# LM3S2139 register map
File version: 7944
Registers are 32-bit, read-write, no defined reset value unless marked. A register's access mark holds for its fields unless they carry their own. Offsets are from the block's base; [hi:lo] are bit positions; {n}, {i} and the like mark numbered series.

## COMP — Register map for COMP peripheral
Base 0x4003C000; register names take the prefix COMP
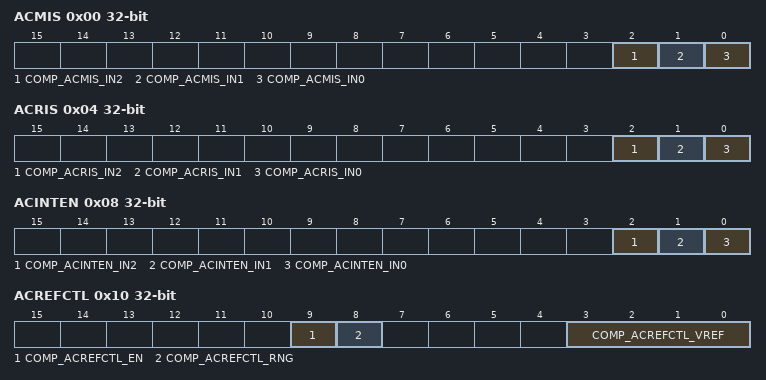
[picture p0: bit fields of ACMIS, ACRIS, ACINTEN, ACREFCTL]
0x00 ACMIS — Analog Comparator Masked Interrupt Status
  [2] COMP_ACMIS_IN2 — Comparator 2 Masked Interrupt Status
  [1] COMP_ACMIS_IN1 — Comparator 1 Masked Interrupt Status
  [0] COMP_ACMIS_IN0 — Comparator 0 Masked Interrupt Status
0x04 ACRIS — Analog Comparator Raw Interrupt Status
  [2] COMP_ACRIS_IN2 — Comparator 2 Interrupt Status
  [1] COMP_ACRIS_IN1 — Comparator 1 Interrupt Status
  [0] COMP_ACRIS_IN0 — Comparator 0 Interrupt Status
0x08 ACINTEN — Analog Comparator Interrupt Enable
  [2] COMP_ACINTEN_IN2 — Comparator 2 Interrupt Enable
  [1] COMP_ACINTEN_IN1 — Comparator 1 Interrupt Enable
  [0] COMP_ACINTEN_IN0 — Comparator 0 Interrupt Enable
0x10 ACREFCTL — Analog Comparator Reference Voltage Control
  [9] COMP_ACREFCTL_EN — Resistor Ladder Enable
  [8] COMP_ACREFCTL_RNG — Resistor Ladder Range
  [3:0] COMP_ACREFCTL_VREF — Resistor Ladder Voltage Ref
{0x20+0x20*i} ACSTAT{i} (i=0..2) — Analog Comparator Status {i}
  [1] COMP_ACSTAT{i}_OVAL — Comparator Output Value
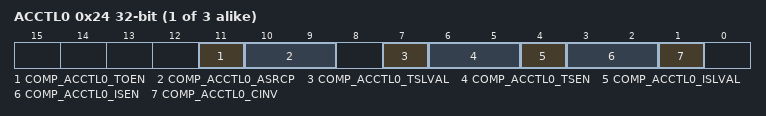
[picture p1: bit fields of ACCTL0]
{0x24+0x20*i} ACCTL{i} (i=0..2) — Analog Comparator Control {i}
  [11] COMP_ACCTL{i}_TOEN — Trigger Output Enable
  [10:9] COMP_ACCTL{i}_ASRCP — Analog Source Positive
    0=COMP_ACCTL{i}_ASRCP_PIN (Pin value of Cn+); 1=COMP_ACCTL{i}_ASRCP_PIN0 (Pin value of C0+); 2=COMP_ACCTL{i}_ASRCP_REF (Internal voltage reference (VIREF))
  [7] COMP_ACCTL{i}_TSLVAL — Trigger Sense Level Value
  [6:5] COMP_ACCTL{i}_TSEN — Trigger Sense
    0=COMP_ACCTL{i}_TSEN_LEVEL (Level sense, see TSLVAL); 1=COMP_ACCTL{i}_TSEN_FALL (Falling edge); 2=COMP_ACCTL{i}_TSEN_RISE (Rising edge); 3=COMP_ACCTL{i}_TSEN_BOTH (Either edge)
  [4] COMP_ACCTL{i}_ISLVAL — Interrupt Sense Level Value
  [3:2] COMP_ACCTL{i}_ISEN — Interrupt Sense
    0=COMP_ACCTL{i}_ISEN_LEVEL (Level sense, see ISLVAL); 1=COMP_ACCTL{i}_ISEN_FALL (Falling edge); 2=COMP_ACCTL{i}_ISEN_RISE (Rising edge); 3=COMP_ACCTL{i}_ISEN_BOTH (Either edge)
  [1] COMP_ACCTL{i}_CINV — Comparator Output Invert

## FLASH_CTRL — Register map for FLASH_CTRL peripheral
Base 0x400FD000; register names take the prefix FLASH_CTRL
0x00 FMA — Flash Memory Address
  [15:0] FLASH_FMA_OFFSET — Address Offset
0x04 FMD — Flash Memory Data
  [31:0] FLASH_FMD_DATA — Data Value
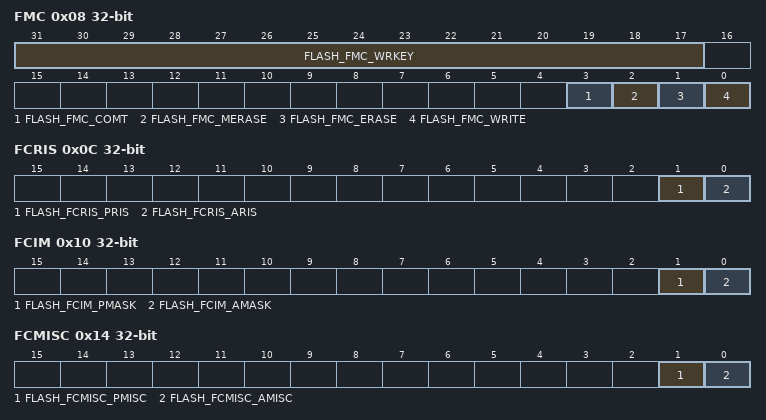
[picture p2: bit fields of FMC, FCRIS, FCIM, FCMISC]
0x08 FMC — Flash Memory Control
  [31:17] FLASH_FMC_WRKEY — FLASH write key
  [3] FLASH_FMC_COMT — Commit Register Value
  [2] FLASH_FMC_MERASE — Mass Erase Flash Memory
  [1] FLASH_FMC_ERASE — Erase a Page of Flash Memory
  [0] FLASH_FMC_WRITE — Write a Word into Flash Memory
0x0C FCRIS — Flash Controller Raw Interrupt Status
  [1] FLASH_FCRIS_PRIS — Programming Raw Interrupt Status
  [0] FLASH_FCRIS_ARIS — Access Raw Interrupt Status
0x10 FCIM — Flash Controller Interrupt Mask
  [1] FLASH_FCIM_PMASK — Programming Interrupt Mask
  [0] FLASH_FCIM_AMASK — Access Interrupt Mask
0x14 FCMISC — Flash Controller Masked Interrupt Status and Clear
  [1] FLASH_FCMISC_PMISC — Programming Masked Interrupt Status and Clear
  [0] FLASH_FCMISC_AMISC — Access Masked Interrupt Status and Clear
0x1140 USECRL — USec Reload
  [7:0] FLASH_USECRL — Microsecond Reload Value
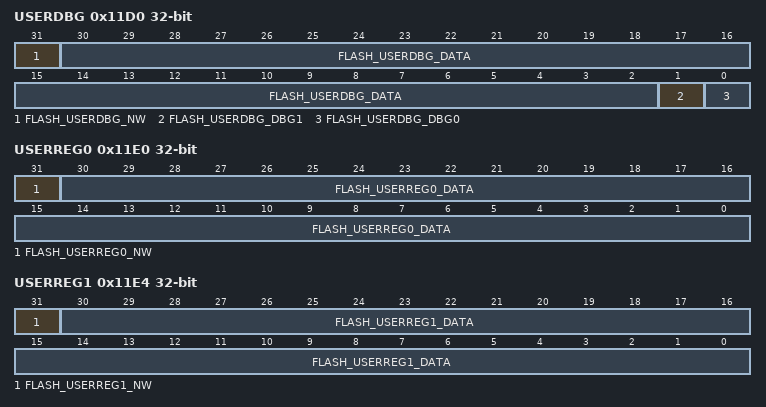
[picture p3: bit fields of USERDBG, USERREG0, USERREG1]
0x11D0 USERDBG (FLASH_ALT view) — User Debug
  [31] FLASH_USERDBG_NW — User Debug Not Written
  [30:2] FLASH_USERDBG_DATA — User Data
  [1] FLASH_USERDBG_DBG1 — Debug Control 1
  [0] FLASH_USERDBG_DBG0 — Debug Control 0
0x11E0 USERREG0 — User Register 0
  [31] FLASH_USERREG0_NW — Not Written
  [30:0] FLASH_USERREG0_DATA — User Data
0x11E4 USERREG1 — User Register 1
  [31] FLASH_USERREG1_NW — Not Written
  [30:0] FLASH_USERREG1_DATA — User Data
{0x1200+4i} FMPRE{i} (i=0..3) — Flash Memory Protection Read Enable {i}
{0x1400+4i} FMPPE{i} (i=0..3) — Flash Memory Protection Program Enable {i}
